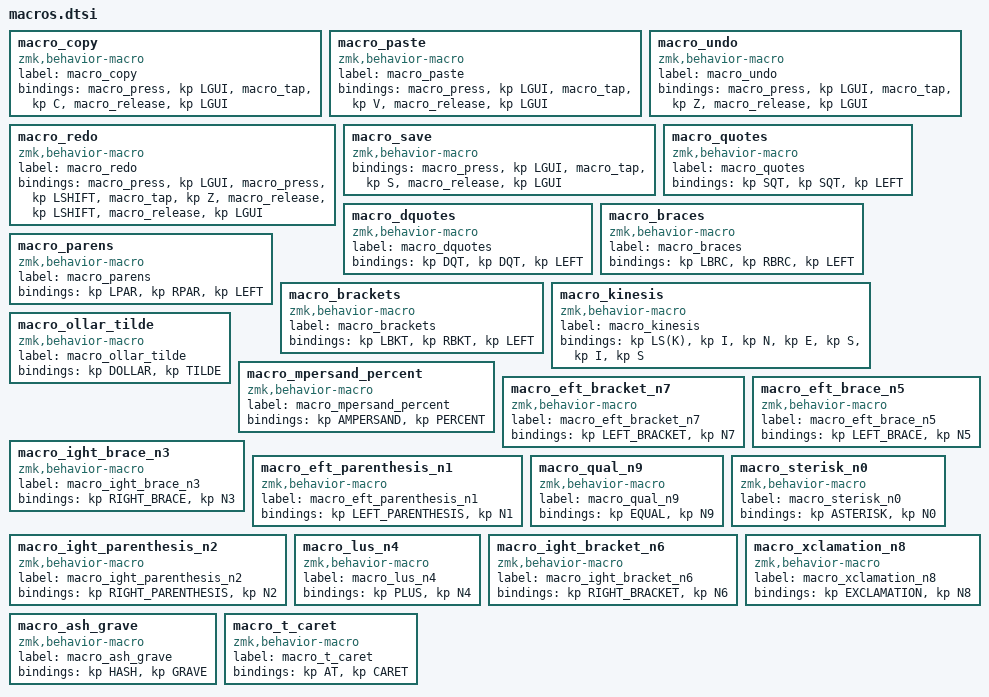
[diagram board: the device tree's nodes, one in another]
macro_copy: macro_copy{
compatible = "zmk,behavior-macro";
label = "macro_copy";
#binding-cells = <0>;
bindings = <&macro_press &kp LGUI>, <&macro_tap &kp C>, <&macro_release &kp LGUI>;
};
macro_paste: macro_paste{
compatible = "zmk,behavior-macro";
label = "macro_paste";
#binding-cells = <0>;
bindings = <&macro_press &kp LGUI>, <&macro_tap &kp V>, <&macro_release &kp LGUI>;
};
macro_undo: macro_undo{
compatible = "zmk,behavior-macro";
label = "macro_undo";
#binding-cells = <0>;
bindings = <&macro_press &kp LGUI>, <&macro_tap &kp Z>, <&macro_release &kp LGUI>;
};
macro_redo: macro_redo{
compatible = "zmk,behavior-macro";
label = "macro_redo";
#binding-cells = <0>;
bindings = <&macro_press &kp LGUI>, <&macro_press &kp LSHIFT>, <&macro_tap &kp Z>, <&macro_release &kp LSHIFT>, <&macro_release &kp LGUI>;
};
macro_save: macro_save{
compatible = "zmk,behavior-macro";

#binding-cells = <0>;
bindings = <&macro_press &kp LGUI>, <&macro_tap &kp S>, <&macro_release &kp LGUI>;
};
macro_quotes: macro_quotes{
compatible = "zmk,behavior-macro";
label = "macro_quotes";
#binding-cells = <0>;
bindings = <&kp SQT>, <&kp SQT>, <&kp LEFT>;
};
macro_dquotes: macro_dquotes{
compatible = "zmk,behavior-macro";
label = "macro_dquotes";
#binding-cells = <0>;
bindings = <&kp DQT>, <&kp DQT>, <&kp LEFT>;
};
macro_braces: macro_braces{
compatible = "zmk,behavior-macro";
label = "macro_braces";
#binding-cells = <0>;
bindings = <&kp LBRC>, <&kp RBRC>, <&kp LEFT>;
};
macro_parens: macro_parens{
compatible = "zmk,behavior-macro";
label = "macro_parens";
#binding-cells = <0>;
bindings = <&kp LPAR>, <&kp RPAR>, <&kp LEFT>;
};
macro_brackets: macro_brackets{
compatible = "zmk,behavior-macro";
label = "macro_brackets";
#binding-cells = <0>;
bindings = <&kp LBKT>, <&kp RBKT>, <&kp LEFT>;
};
macro_kinesis: macro_kinesis{
compatible = "zmk,behavior-macro";
label = "macro_kinesis";
#binding-cells = <0>;
bindings = <&kp LS(K)>, <&kp I>, <&kp N>, <&kp E>, <&kp S>, <&kp I>, <&kp S>;
};
macro_ollar_tilde: macro_ollar_tilde{
compatible = "zmk,behavior-macro";
label = "macro_ollar_tilde";
#binding-cells = <0>;
bindings = <&kp DOLLAR>, <&kp TILDE>;
};
macro_mpersand_percent: macro_mpersand_percent{
compatible = "zmk,behavior-macro";
label = "macro_mpersand_percent";
#binding-cells = <0>;
bindings = <&kp AMPERSAND>, <&kp PERCENT>;
};
macro_eft_bracket_n7: macro_eft_bracket_n7{
compatible = "zmk,behavior-macro";
label = "macro_eft_bracket_n7";
#binding-cells = <0>;
bindings = <&kp LEFT_BRACKET>, <&kp N7>;
};
macro_eft_brace_n5: macro_eft_brace_n5{
compatible = "zmk,behavior-macro";
label = "macro_eft_brace_n5";
#binding-cells = <0>;
bindings = <&kp LEFT_BRACE>, <&kp N5>;
};
macro_ight_brace_n3: macro_ight_brace_n3{
compatible = "zmk,behavior-macro";
label = "macro_ight_brace_n3";
#binding-cells = <0>;
bindings = <&kp RIGHT_BRACE>, <&kp N3>;
};
macro_eft_parenthesis_n1: macro_eft_parenthesis_n1{
compatible = "zmk,behavior-macro";
label = "macro_eft_parenthesis_n1";
#binding-cells = <0>;
bindings = <&kp LEFT_PARENTHESIS>, <&kp N1>;
};
macro_qual_n9: macro_qual_n9{
compatible = "zmk,behavior-macro";
label = "macro_qual_n9";
#binding-cells = <0>;
bindings = <&kp EQUAL>, <&kp N9>;
};
macro_sterisk_n0: macro_sterisk_n0{
compatible = "zmk,behavior-macro";
label = "macro_sterisk_n0";
#binding-cells = <0>;
bindings = <&kp ASTERISK>, <&kp N0>;
};
macro_ight_parenthesis_n2: macro_ight_parenthesis_n2{
compatible = "zmk,behavior-macro";
label = "macro_ight_parenthesis_n2";
#binding-cells = <0>;
bindings = <&kp RIGHT_PARENTHESIS>, <&kp N2>;
};
macro_lus_n4: macro_lus_n4{
compatible = "zmk,behavior-macro";
label = "macro_lus_n4";
#binding-cells = <0>;
bindings = <&kp PLUS>, <&kp N4>;
};
macro_ight_bracket_n6: macro_ight_bracket_n6{
compatible = "zmk,behavior-macro";
label = "macro_ight_bracket_n6";
#binding-cells = <0>;
bindings = <&kp RIGHT_BRACKET>, <&kp N6>;
};
macro_xclamation_n8: macro_xclamation_n8{
compatible = "zmk,behavior-macro";
label = "macro_xclamation_n8";
#binding-cells = <0>;
bindings = <&kp EXCLAMATION>, <&kp N8>;
};
macro_ash_grave: macro_ash_grave{
compatible = "zmk,behavior-macro";
label = "macro_ash_grave";
#binding-cells = <0>;
bindings = <&kp HASH>, <&kp GRAVE>;
};
macro_t_caret: macro_t_caret{
compatible = "zmk,behavior-macro";
label = "macro_t_caret";
#binding-cells = <0>;
bindings = <&kp AT>, <&kp CARET>;
};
